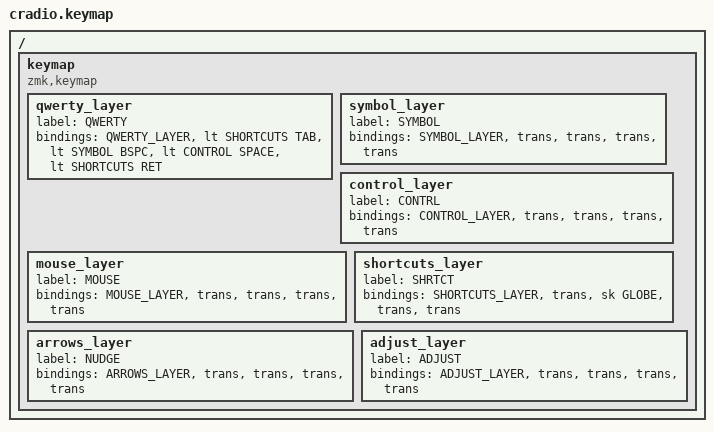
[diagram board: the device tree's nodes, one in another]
/*
 * Copyright (c) 2020 The ZMK Contributors
 *
 * SPDX-License-Identifier: MIT
 */

#include <behaviors.dtsi>
#include <dt-bindings/zmk/bt.h>
#include <dt-bindings/zmk/keys.h>
#include <dt-bindings/zmk/matrix_transform.h>
#include <dt-bindings/zmk/outputs.h>
#include <dt-bindings/zmk/pointing.h>
#include "shared.dtsi"

/ {
  keymap {
    compatible = "zmk,keymap";

    qwerty_layer {
      label = "QWERTY";
      bindings = <
QWERTY_LAYER
&lt SHORTCUTS TAB &lt SYMBOL BSPC &lt CONTROL SPACE &lt SHORTCUTS RET
      >;
    };

    symbol_layer {
      label = "SYMBOL";
      bindings = <
SYMBOL_LAYER
&trans &trans &trans &trans
      >;
    };

    control_layer {
      label = "CONTRL";
      bindings = <
CONTROL_LAYER
&trans &trans &trans &trans
      >;
    };

    mouse_layer {
      label = "MOUSE";
      bindings = <
MOUSE_LAYER
&trans &trans &trans &trans
      >;
    };

    shortcuts_layer {
      label = "SHRTCT";
      bindings = <
SHORTCUTS_LAYER
&trans &sk GLOBE &trans &trans
      >;
    };

    arrows_layer {
      label = "NUDGE";
      bindings = <
ARROWS_LAYER
&trans &trans &trans &trans
      >;
    };

    adjust_layer {
      label = "ADJUST";
      bindings = <
ADJUST_LAYER
&trans &trans &trans &trans
      >;
   };

  };
};

